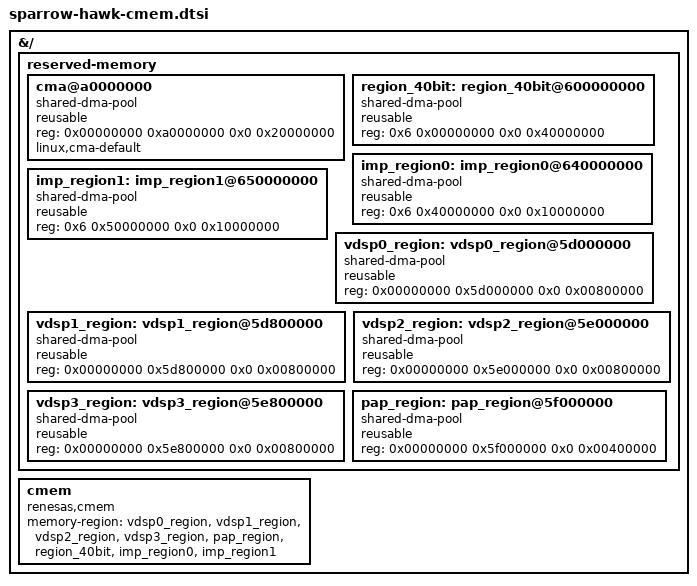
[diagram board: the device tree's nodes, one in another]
// SPDX-License-Identifier: GPL-2.0+
/*
 * Copyright (C) 2026 Renesas Electronics Corporation
 */

/dts-v1/;
/plugin/;

&{/} {
	reserved-memory {
		#address-cells = <2>;
		#size-cells = <2>;
		ranges;

		cma@a0000000 {
			compatible = "shared-dma-pool";
			reusable;
			reg = <0x00000000 0xa0000000 0x0 0x20000000>;
			linux,cma-default;
		};

		/* cmem_other5 : 40-bit, 1024 MiB */
		region_40bit: region_40bit@600000000 {
			compatible = "shared-dma-pool";
			reusable;
			reg = <0x6 0x00000000 0x0 0x40000000>;  /* 1024 MiB */
		};

		/* cmem_other6 : QM/ECC-off, 256 MiB */
		imp_region0: imp_region0@640000000 {
			compatible = "shared-dma-pool";
			reusable;
			reg = <0x6 0x40000000 0x0 0x10000000>;  /* 256 MiB */
		};

		/* cmem_other7 : QM/ECC-off, 256 MiB */
		imp_region1: imp_region1@650000000 {
			compatible = "shared-dma-pool";
			reusable;
			reg = <0x6 0x50000000 0x0 0x10000000>;  /* 256 MiB */
		};

		vdsp0_region: vdsp0_region@5d000000 {
			compatible = "shared-dma-pool";
			reusable;
			reg = <0x00000000 0x5d000000 0x0 0x00800000>;
		};
		vdsp1_region: vdsp1_region@5d800000 {
			compatible = "shared-dma-pool";
			reusable;
			reg = <0x00000000 0x5d800000 0x0 0x00800000>;
		};
		vdsp2_region: vdsp2_region@5e000000 {
			compatible = "shared-dma-pool";
			reusable;
			reg = <0x00000000 0x5e000000 0x0 0x00800000>;
		};
		vdsp3_region: vdsp3_region@5e800000 {
			compatible = "shared-dma-pool";
			reusable;
			reg = <0x00000000 0x5e800000 0x0 0x00800000>;
		};

		pap_region: pap_region@5f000000 {
			compatible = "shared-dma-pool";
			reusable;
			reg = <0x00000000 0x5f000000 0x0 0x00400000>;
		};
	};

	cmem {
		compatible = "renesas,cmem";
		memory-region = <&vdsp0_region &vdsp1_region
						&vdsp2_region &vdsp3_region
						&pap_region &region_40bit
						&imp_region0 &imp_region1>;
	};
};
